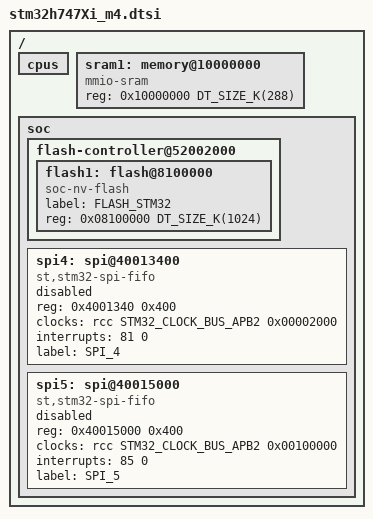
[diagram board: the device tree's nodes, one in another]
/*
 * Copyright (c) 2019 Linaro Limited
 *
 * SPDX-License-Identifier: Apache-2.0
 */

#include <mem.h>
#include <st/h7/stm32h747.dtsi>

/ {
	cpus {
		/delete-node/ cpu@0;
	};

	/* system data RAM accessible over over AXI bus */
	sram1: memory@10000000 {
		reg = <0x10000000 DT_SIZE_K(288)>;
		compatible = "mmio-sram";
	};

	soc {
		flash-controller@52002000 {
			flash1: flash@8100000 {
				compatible = "soc-nv-flash";
				label = "FLASH_STM32";
				reg = <0x08100000 DT_SIZE_K(1024)>;
			};
		};

		spi4: spi@40013400 {
			compatible = "st,stm32-spi-fifo", "st,stm32-spi";
			#address-cells = <1>;
			#size-cells = <0>;
			reg = <0x4001340 0x400>;
			clocks = <&rcc STM32_CLOCK_BUS_APB2 0x00002000>;
			interrupts = <81 0>;
			status = "disabled";
			label = "SPI_4";
		};

		spi5: spi@40015000 {
			compatible = "st,stm32-spi-fifo", "st,stm32-spi";
			#address-cells = <1>;
			#size-cells = <0>;
			reg = <0x40015000 0x400>;
			clocks = <&rcc STM32_CLOCK_BUS_APB2 0x00100000>;
			interrupts = <85 0>;
			status = "disabled";
			label = "SPI_5";
		};
	};
};
